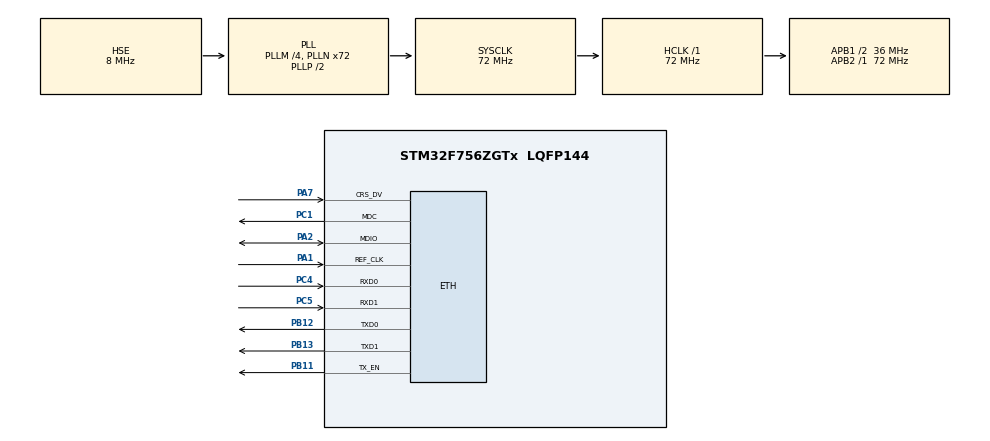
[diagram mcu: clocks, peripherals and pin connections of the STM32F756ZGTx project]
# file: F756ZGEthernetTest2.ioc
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ETH.MediaInterface=HAL_ETH_RMII_MODE
FREERTOS.Tasks01=defaultTask,0,512,StartDefaultTask,Default,NULL,Dynamic,NULL,NULL
FREERTOS.configUSE_NEWLIB_REENTRANT=1
FREERTOS.copyHeapFile=1
LWIP.BSP.number=1
LWIP.GATEWAY_ADDRESS=192.168.010.001
LWIP.IP_ADDRESS=192.168.010.050
LWIP.LWIP_DHCP=0
LWIP.NETMASK_ADDRESS=255.255.255.000
LWIP.Version=v2.1.2_Cube
LWIP0.BSP.STBoard=false
LWIP0.BSP.api=BSP_COMPONENT_DRIVER
LWIP0.BSP.component=LAN8742
LWIP0.BSP.instance=LAN8742
LWIP0.BSP.name=Driver_PHY
LWIP0.BSP.semaphore=S_LAN8742
LWIP0.BSP.solution=LAN8742
Mcu.Family=STM32F7
Mcu.Name=STM32F756ZGTx
Mcu.Package=LQFP144
NVIC.ETH_IRQn=true\:5\:0\:false\:false\:true\:true\:false\:true\:true
NVIC.PriorityGroup=NVIC_PRIORITYGROUP_4
NVIC.TIM8_TRG_COM_TIM14_IRQn=true\:15\:0\:false\:false\:true\:false\:false\:true\:true
NVIC.TimeBase=TIM8_TRG_COM_TIM14_IRQn
NVIC.TimeBaseIP=TIM14
PA1.Mode=RMII
PA1.Signal=ETH_REF_CLK
PA13.Mode=Serial_Wire
PA13.Signal=SYS_JTMS-SWDIO
PA14.Mode=Serial_Wire
PA14.Signal=SYS_JTCK-SWCLK
PA2.Mode=RMII
PA2.Signal=ETH_MDIO
PA7.Mode=RMII
PA7.Signal=ETH_CRS_DV
PB11.Mode=RMII
PB11.Signal=ETH_TX_EN
PB12.Mode=RMII
PB12.Signal=ETH_TXD0
PB13.Mode=RMII
PB13.Signal=ETH_TXD1
PC1.Mode=RMII
PC1.Signal=ETH_MDC
PC4.Mode=RMII
PC4.Signal=ETH_RXD0
PC5.Mode=RMII
PC5.Signal=ETH_RXD1
PH0/OSC_IN.Mode=HSE-External-Clock-Source
PH0/OSC_IN.Signal=RCC_OSC_IN
PH1/OSC_OUT.Mode=HSE-External-Clock-Source
PH1/OSC_OUT.Signal=RCC_OSC_OUT
ProjectManager.HeapSize=0x200
ProjectManager.StackSize=0x400
ProjectManager.TargetToolchain=STM32CubeIDE
RCC.48MHZClocksFreq_Value=24000000
RCC.AHBFreq_Value=72000000
RCC.APB1CLKDivider=RCC_HCLK_DIV2
RCC.APB1Freq_Value=36000000
RCC.APB1TimFreq_Value=72000000
RCC.APB2Freq_Value=72000000
RCC.APB2TimFreq_Value=72000000
RCC.CortexFreq_Value=72000000
RCC.HCLKFreq_Value=72000000
RCC.HSE_VALUE=8000000
RCC.HSI_VALUE=16000000
RCC.PLLM=4
RCC.PLLMUL=RCC_PLL_MUL9
RCC.PLLN=72
RCC.PLLQ=3
RCC.PLLSourceVirtual=RCC_PLLSOURCE_HSE
RCC.PRESCALERUSB=RCC_USBCLKSOURCE_PLL_DIV1_5
RCC.SYSCLKFreq_VALUE=72000000
RCC.SYSCLKSource=RCC_SYSCLKSOURCE_PLLCLK
RCC.SYSCLKSourceVirtual=RCC_SYSCLKSOURCE_PLLCLK
RCC.USBFreq_Value=48000000
RCC.VCOOutputFreq_Value=144000000
VP_FREERTOS_VS_CMSIS_V1.Mode=CMSIS_V1
VP_LWIP_VS_Enabled.Mode=Enabled
VP_SYS_VS_tim14.Mode=TIM14
board=NUCLEO-F756ZG

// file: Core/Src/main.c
/* USER CODE BEGIN Header */
/**
  ******************************************************************************
  * @file           : main.c
  * @brief          : Main program body
  ******************************************************************************
  * @attention
  *
  * Copyright (c) 2022 STMicroelectronics.
  * All rights reserved.
  *
  * This software is licensed under terms that can be found in the LICENSE file
  * in the root directory of this software component.
  * If no LICENSE file comes with this software, it is provided AS-IS.
  *
  ******************************************************************************
  */
/* USER CODE END Header */
#include "main.h"
#include "cmsis_os.h"
#include "lwip.h"

osThreadId defaultTaskHandle;

void SystemClock_Config(void);
static void MX_GPIO_Init(void);
void StartDefaultTask(void const * argument);

int main(void)
{

  /* MCU Configuration--------------------------------------------------------*/

  /* Reset of all peripherals, Initializes the Flash interface and the Systick. */
  HAL_Init();

  /* Configure the system clock */
  SystemClock_Config();

  /* Initialize all configured peripherals */
  MX_GPIO_Init();

  /* Create the thread(s) */
  /* definition and creation of defaultTask */
  osThreadDef(defaultTask, StartDefaultTask, osPriorityNormal, 0, 512);
  defaultTaskHandle = osThreadCreate(osThread(defaultTask), NULL);

  /* Start scheduler */
  osKernelStart();

  /* We should never get here as control is now taken by the scheduler */
  /* Infinite loop */
  while (1)
  {

  }
}

void SystemClock_Config(void)
{
  RCC_OscInitTypeDef RCC_OscInitStruct = {0};
  RCC_ClkInitTypeDef RCC_ClkInitStruct = {0};

  /** Configure the main internal regulator output voltage
  */
  __HAL_RCC_PWR_CLK_ENABLE();
  __HAL_PWR_VOLTAGESCALING_CONFIG(PWR_REGULATOR_VOLTAGE_SCALE3);

  /** Initializes the RCC Oscillators according to the specified parameters
  * in the RCC_OscInitTypeDef structure.
  */
  RCC_OscInitStruct.OscillatorType = RCC_OSCILLATORTYPE_HSE;
  RCC_OscInitStruct.HSEState = RCC_HSE_BYPASS;
  RCC_OscInitStruct.PLL.PLLState = RCC_PLL_ON;
  RCC_OscInitStruct.PLL.PLLSource = RCC_PLLSOURCE_HSE;
  RCC_OscInitStruct.PLL.PLLM = 4;
  RCC_OscInitStruct.PLL.PLLN = 72;
  RCC_OscInitStruct.PLL.PLLP = RCC_PLLP_DIV2;
  RCC_OscInitStruct.PLL.PLLQ = 3;
  if (HAL_RCC_OscConfig(&RCC_OscInitStruct) != HAL_OK)
  {
    Error_Handler();
  }

  /** Initializes the CPU, AHB and APB buses clocks
  */
  RCC_ClkInitStruct.ClockType = RCC_CLOCKTYPE_HCLK|RCC_CLOCKTYPE_SYSCLK
                              |RCC_CLOCKTYPE_PCLK1|RCC_CLOCKTYPE_PCLK2;
  RCC_ClkInitStruct.SYSCLKSource = RCC_SYSCLKSOURCE_PLLCLK;
  RCC_ClkInitStruct.AHBCLKDivider = RCC_SYSCLK_DIV1;
  RCC_ClkInitStruct.APB1CLKDivider = RCC_HCLK_DIV2;
  RCC_ClkInitStruct.APB2CLKDivider = RCC_HCLK_DIV1;

  if (HAL_RCC_ClockConfig(&RCC_ClkInitStruct, FLASH_LATENCY_2) != HAL_OK)
  {
    Error_Handler();
  }
}

static void MX_GPIO_Init(void)
{

  /* GPIO Ports Clock Enable */
  __HAL_RCC_GPIOH_CLK_ENABLE();
  __HAL_RCC_GPIOC_CLK_ENABLE();
  __HAL_RCC_GPIOA_CLK_ENABLE();
  __HAL_RCC_GPIOB_CLK_ENABLE();

}

void StartDefaultTask(void const * argument)
{
  /* init code for LWIP */
  MX_LWIP_Init();
  /* USER CODE BEGIN 5 */
  /*struct udp_pcb *pcb;
    struct pbuf *p;
    err_t err;
    ip4_addr_t dst_addr;
    const unsigned short src_port = 12345;
    const unsigned short dst_port = 8080;

    IP4_ADDR(&dst_addr,192,168,10,108);

    pcb = udp_new();
    err = udp_bind(pcb, IP_ADDR_ANY, src_port);

    uint32_t cnt = 0;*/
  /* Infinite loop */
  for(;;)
  {
	/*  p = pbuf_alloc(PBUF_TRANSPORT, sizeof(4), PBUF_RAM);
	      *(uint32_t *)p->payload = cnt++;
	      p->len = 4;
	      err = udp_sendto(pcb, p, &dst_addr, dst_port);
	      pbuf_free(p);*/
    osDelay(1000);
  }
  /* USER CODE END 5 */
}

void HAL_TIM_PeriodElapsedCallback(TIM_HandleTypeDef *htim)
{
  if (htim->Instance == TIM14) {
    HAL_IncTick();
  }
}

void Error_Handler(void)
{
  __disable_irq();
  while (1)
  {
  }
}
